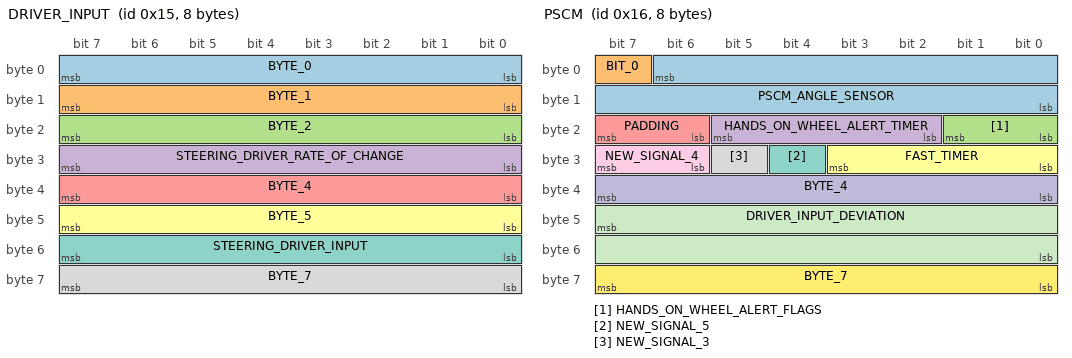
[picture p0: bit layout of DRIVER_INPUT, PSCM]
BO_ 21 DRIVER_INPUT: 8 XXX
 SG_ BYTE_0 : 7|8@0+ (1,0) [0|255] "" XXX
 SG_ BYTE_1 : 15|8@0+ (1,0) [0|255] "" XXX
 SG_ BYTE_2 : 16|8@1+ (1,0) [0|255] "" XXX
 SG_ STEERING_DRIVER_RATE_OF_CHANGE : 31|8@0- (1,0) [0|255] "" XXX
 SG_ BYTE_4 : 39|8@0+ (1,0) [0|255] "" XXX
 SG_ BYTE_5 : 40|8@1+ (1,0) [0|255] "" XXX
 SG_ STEERING_DRIVER_INPUT : 55|8@0- (1,1) [0|255] "" XXX
 SG_ BYTE_7 : 63|8@0+ (1,0) [0|255] "" XXX

BO_ 22 PSCM: 8 XXX
 SG_ PSCM_ANGLE_SENSOR : 6|15@0- (0.05596,0) [-916|916] "º" XXX
 SG_ BIT_0 : 7|1@0+ (1,0) [0|1] "" XXX
 SG_ HANDS_ON_WHEEL_ALERT_FLAGS : 17|2@0+ (1,0) [0|3] "" XXX
 SG_ HANDS_ON_WHEEL_ALERT_TIMER : 21|4@0+ (1,0) [0|15] "" XXX
 SG_ PADDING : 23|2@0+ (1,0) [0|3] "" XXX
 SG_ FAST_TIMER : 27|4@0+ (1,0) [0|15] "" XXX
 SG_ NEW_SIGNAL_5 : 28|1@0+ (1,0) [0|1] "" XXX
 SG_ NEW_SIGNAL_3 : 29|1@0+ (1,0) [0|1] "" XXX
 SG_ NEW_SIGNAL_4 : 31|2@0+ (1,0) [0|3] "" XXX
 SG_ BYTE_4 : 39|8@0+ (1,0) [0|255] "" XXX
 SG_ DRIVER_INPUT_DEVIATION : 47|16@0- (1,0) [0|65535] "" XXX
 SG_ BYTE_7 : 63|8@0+ (1,0) [0|255] "" XXX

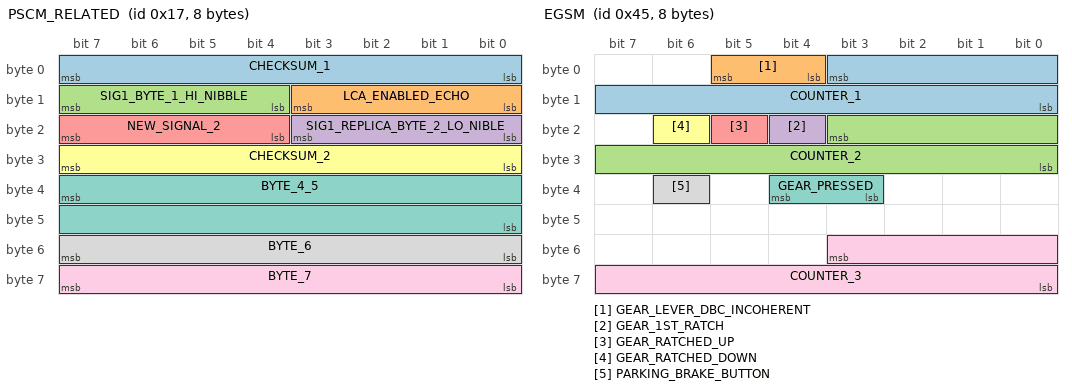
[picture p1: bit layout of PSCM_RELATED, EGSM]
BO_ 23 PSCM_RELATED: 8 XXX
 SG_ CHECKSUM_1 : 7|8@0+ (1,0) [0|255] "" XXX
 SG_ LCA_ENABLED_ECHO : 11|4@0+ (1,0) [0|15] "" XXX
 SG_ SIG1_BYTE_1_HI_NIBBLE : 15|4@0+ (1,0) [0|15] "" XXX
 SG_ SIG1_REPLICA_BYTE_2_LO_NIBLE : 19|4@0+ (1,0) [0|15] "" XXX
 SG_ NEW_SIGNAL_2 : 23|4@0+ (1,0) [0|15] "" XXX
 SG_ CHECKSUM_2 : 31|8@0+ (1,0) [0|255] "" XXX
 SG_ BYTE_4_5 : 39|16@0+ (1,0) [0|65535] "" XXX
 SG_ BYTE_6 : 55|8@0+ (1,0) [0|255] "" XXX
 SG_ BYTE_7 : 63|8@0+ (1,0) [0|255] "" XXX

BO_ 69 EGSM: 8 XXX
 SG_ COUNTER_1 : 3|12@0+ (1,0) [0|4095] "" XXX
 SG_ GEAR_LEVER_DBC_INCOHERENT : 5|2@0+ (1,0) [0|3] "" XXX
 SG_ COUNTER_2 : 19|12@0+ (1,0) [0|4095] "" XXX
 SG_ GEAR_1ST_RATCH : 20|1@0+ (1,0) [0|1] "" XXX
 SG_ GEAR_RATCHED_UP : 21|1@0+ (1,0) [0|1] "" XXX
 SG_ GEAR_RATCHED_DOWN : 22|1@0+ (1,0) [0|1] "" XXX
 SG_ GEAR_PRESSED : 36|2@0+ (1,0) [0|3] "" XXX
 SG_ PARKING_BRAKE_BUTTON : 38|1@0+ (1,0) [0|1] "" XXX
 SG_ COUNTER_3 : 51|12@0+ (1,0) [0|4095] "" XXX

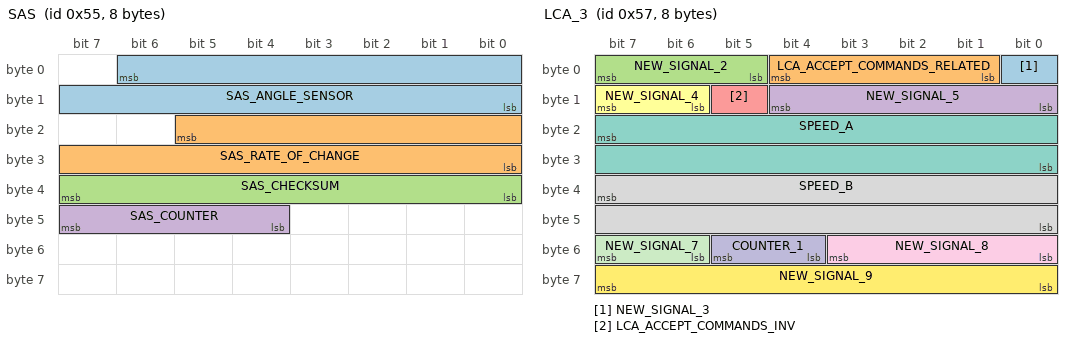
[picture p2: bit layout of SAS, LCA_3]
BO_ 85 SAS: 8 XXX
 SG_ SAS_ANGLE_SENSOR : 6|15@0- (0.05596,0) [0|32767] "º" XXX
 SG_ SAS_RATE_OF_CHANGE : 21|14@0- (1,0) [0|16383] "" XXX
 SG_ SAS_CHECKSUM : 39|8@0+ (1,0) [0|4095] "" XXX
 SG_ SAS_COUNTER : 44|4@1+ (1,0) [0|15] "" XXX

BO_ 87 LCA_3: 8 XXX
 SG_ NEW_SIGNAL_3 : 0|1@0+ (1,0) [0|1] "" XXX
 SG_ LCA_ACCEPT_COMMANDS_RELATED : 4|4@0+ (1,0) [0|15] "" XXX
 SG_ NEW_SIGNAL_2 : 7|3@0+ (1,0) [0|7] "" XXX
 SG_ NEW_SIGNAL_5 : 12|5@0+ (1,0) [0|31] "" XXX
 SG_ LCA_ACCEPT_COMMANDS_INV : 13|1@0+ (1,0) [0|1] "" XXX
 SG_ NEW_SIGNAL_4 : 15|2@0+ (1,0) [0|3] "" XXX
 SG_ SPEED_A : 23|16@0+ (1,0) [0|65535] "" XXX
 SG_ SPEED_B : 39|16@0+ (1,0) [0|65535] "" XXX
 SG_ NEW_SIGNAL_8 : 51|4@0+ (1,0) [0|15] "" XXX
 SG_ COUNTER_1 : 53|2@0+ (1,0) [0|3] "" XXX
 SG_ NEW_SIGNAL_7 : 55|2@0+ (1,0) [0|3] "" XXX
 SG_ NEW_SIGNAL_9 : 63|8@0+ (1,0) [0|255] "" XXX

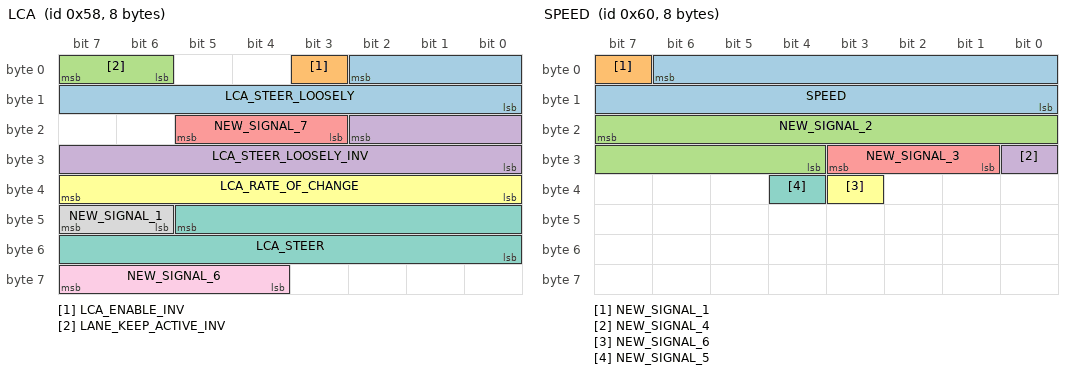
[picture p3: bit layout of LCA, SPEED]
BO_ 88 LCA: 8 XXX
 SG_ LCA_STEER_LOOSELY : 2|11@0- (1,0) [0|2047] "" XXX
 SG_ LCA_ENABLE_INV : 3|1@0+ (1,0) [0|1] "" XXX
 SG_ LANE_KEEP_ACTIVE_INV : 7|2@0+ (1,0) [0|3] "" XXX
 SG_ LCA_STEER_LOOSELY_INV : 18|11@0- (1,0) [0|2047] "" XXX
 SG_ NEW_SIGNAL_7 : 21|3@0+ (1,0) [0|7] "" XXX
 SG_ LCA_RATE_OF_CHANGE : 39|8@0+ (1,0) [0|255] "" XXX
 SG_ LCA_STEER : 45|14@0- (1,0) [0|16383] "" XXX
 SG_ NEW_SIGNAL_1 : 47|2@0+ (1,0) [0|3] "" XXX
 SG_ NEW_SIGNAL_6 : 60|4@1+ (1,0) [0|15] "" XXX

BO_ 96 SPEED: 8 XXX
 SG_ SPEED : 6|15@0+ (1,0) [0|32767] "" XXX
 SG_ NEW_SIGNAL_1 : 7|1@0+ (1,0) [0|1] "" XXX
 SG_ NEW_SIGNAL_2 : 23|12@0+ (1,0) [0|4095] "" XXX
 SG_ NEW_SIGNAL_4 : 24|1@0+ (1,0) [0|1] "" XXX
 SG_ NEW_SIGNAL_3 : 27|3@0+ (1,0) [0|7] "" XXX
 SG_ NEW_SIGNAL_6 : 35|1@0+ (1,0) [0|1] "" XXX
 SG_ NEW_SIGNAL_5 : 36|1@0+ (1,0) [0|1] "" XXX

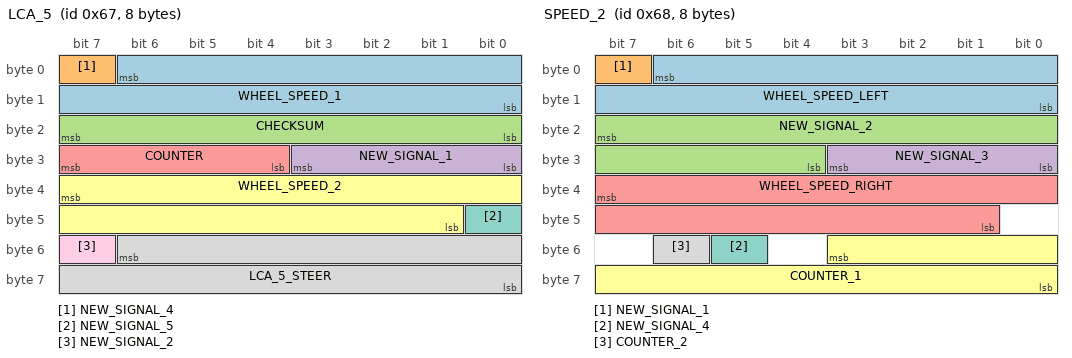
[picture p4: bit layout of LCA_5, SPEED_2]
BO_ 103 LCA_5: 8 XXX
 SG_ WHEEL_SPEED_1 : 6|15@0+ (0.1,0) [0|255] "rpm" XXX
 SG_ NEW_SIGNAL_4 : 7|1@0+ (1,0) [0|1] "" XXX
 SG_ CHECKSUM : 23|8@0+ (1,0) [0|4095] "" XXX
 SG_ NEW_SIGNAL_1 : 24|4@1+ (1,0) [0|15] "" XXX
 SG_ COUNTER : 28|4@1+ (1,0) [0|15] "" XXX
 SG_ WHEEL_SPEED_2 : 39|15@0+ (0.1,0) [0|32767] "rpm" XXX
 SG_ NEW_SIGNAL_5 : 40|1@0+ (1,0) [0|1] "" XXX
 SG_ LCA_5_STEER : 54|15@0- (0.05596,0) [0|32767] "deg" XXX
 SG_ NEW_SIGNAL_2 : 55|1@0+ (1,0) [0|1] "" XXX

BO_ 104 SPEED_2: 8 XXX
 SG_ WHEEL_SPEED_LEFT : 6|15@0+ (1,0) [0|32767] "" XXX
 SG_ NEW_SIGNAL_1 : 7|1@0+ (1,0) [0|1] "" XXX
 SG_ NEW_SIGNAL_2 : 23|12@0+ (1,0) [0|4095] "" XXX
 SG_ NEW_SIGNAL_3 : 27|4@0+ (1,0) [0|15] "" XXX
 SG_ WHEEL_SPEED_RIGHT : 39|15@0+ (1,0) [0|32767] "" XXX
 SG_ COUNTER_1 : 51|12@0+ (1,0) [0|4095] "" XXX
 SG_ NEW_SIGNAL_4 : 53|1@0+ (1,0) [0|1] "" XXX
 SG_ COUNTER_2 : 54|1@0+ (1,0) [0|1] "" XXX

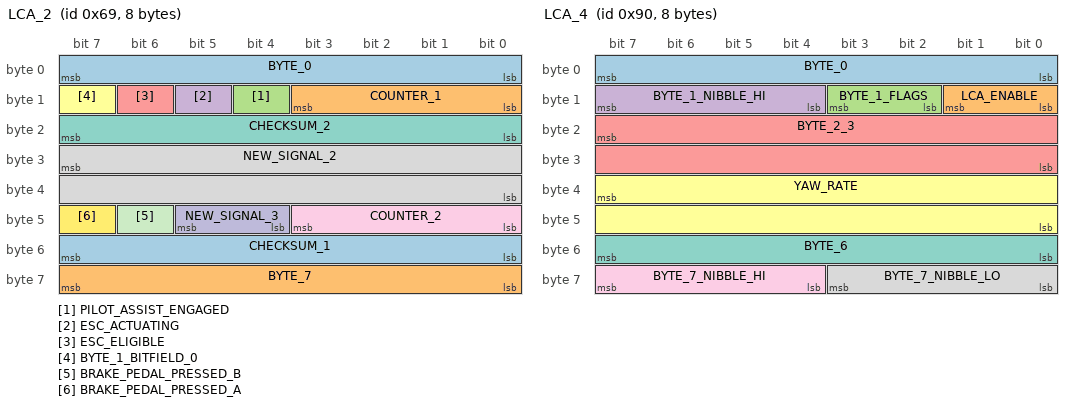
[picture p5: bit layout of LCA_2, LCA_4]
BO_ 105 LCA_2: 8 XXX
 SG_ BYTE_0 : 7|8@0+ (1,0) [0|2047] "" XXX
 SG_ COUNTER_1 : 11|4@0+ (1,0) [0|4095] "" XXX
 SG_ PILOT_ASSIST_ENGAGED : 12|1@0+ (1,0) [0|1] "" XXX
 SG_ ESC_ACTUATING : 13|1@0+ (1,0) [0|1] "" XXX
 SG_ ESC_ELIGIBLE : 14|1@0+ (1,0) [0|1] "" XXX
 SG_ BYTE_1_BITFIELD_0 : 15|1@0+ (1,0) [0|7] "" XXX
 SG_ CHECKSUM_2 : 23|8@0+ (1,0) [0|255] "" XXX
 SG_ NEW_SIGNAL_2 : 31|16@0+ (1,0) [0|65535] "" XXX
 SG_ COUNTER_2 : 43|4@0+ (1,0) [0|4095] "" XXX
 SG_ NEW_SIGNAL_3 : 45|2@0+ (1,0) [0|3] "" XXX
 SG_ BRAKE_PEDAL_PRESSED_B : 46|1@0+ (1,0) [0|1] "" XXX
 SG_ BRAKE_PEDAL_PRESSED_A : 47|1@0+ (-1,1) [0|1] "" XXX
 SG_ CHECKSUM_1 : 55|8@0+ (1,0) [0|255] "" XXX
 SG_ BYTE_7 : 63|8@0+ (1,0) [0|255] "" XXX

BO_ 128 GEAR_POSITION: 8 XXX
 SG_ NEW_SIGNAL_3 : 3|4@0+ (1,0) [0|15] "" XXX
 SG_ NEW_SIGNAL_2 : 4|1@0+ (1,0) [0|1] "" XXX
 SG_ NEW_SIGNAL_1 : 7|3@0+ (1,0) [0|7] "" XXX
 SG_ NEW_SIGNAL_5 : 11|4@0+ (1,0) [0|15] "" XXX
 SG_ NEW_SIGNAL_4 : 15|4@0+ (1,0) [0|15] "" XXX
 SG_ NEW_SIGNAL_17 : 17|2@0+ (1,0) [0|3] "" XXX
 SG_ AEB_A : 18|1@0+ (1,0) [0|1] "" XXX
 SG_ NEW_SIGNAL_18 : 19|1@0+ (1,0) [0|1] "" XXX
 SG_ AEB_B : 20|1@0+ (1,0) [0|1] "" XXX
 SG_ NEW_SIGNAL_6 : 23|3@0+ (1,0) [0|255] "" XXX
 SG_ NEW_SIGNAL_7 : 24|8@1+ (1,0) [0|255] "" XXX
 SG_ NEW_SIGNAL_8 : 39|8@0+ (1,0) [0|255] "" XXX
 SG_ NEW_SIGNAL_13 : 43|4@0+ (1,0) [0|15] "" XXX
 SG_ NEW_SIGNAL_10 : 46|3@0+ (1,0) [0|7] "" XXX
 SG_ NEW_SIGNAL_9 : 47|1@0+ (1,0) [0|1] "" XXX
 SG_ NEW_SIGNAL_14 : 51|4@0+ (1,0) [0|15] "" XXX
 SG_ NEW_SIGNAL_12 : 54|3@0+ (1,0) [0|7] "" XXX
 SG_ NEW_SIGNAL_11 : 55|1@0+ (1,0) [0|1] "" XXX
 SG_ GEAR_POSITION : 58|3@0+ (1,0) [0|7] "" XXX
 SG_ NEW_SIGNAL_16 : 62|4@0+ (1,0) [0|15] "" XXX
 SG_ NEW_SIGNAL_15 : 63|1@0+ (1,0) [0|1] "" XXX

BO_ 144 LCA_4: 8 XXX
 SG_ BYTE_0 : 7|8@0+ (1,0) [0|16383] "" XXX
 SG_ LCA_ENABLE : 9|2@0+ (1,0) [0|3] "" XXX
 SG_ BYTE_1_FLAGS : 11|2@0+ (1,0) [0|3] "" XXX
 SG_ BYTE_1_NIBBLE_HI : 15|4@0+ (1,0) [0|63] "" XXX
 SG_ BYTE_2_3 : 23|16@0- (1,0) [0|65535] "" XXX
 SG_ YAW_RATE : 39|16@0- (1,0) [0|65535] "" XXX
 SG_ BYTE_6 : 55|8@0+ (1,0) [0|255] "" XXX
 SG_ BYTE_7_NIBBLE_LO : 59|4@0+ (1,0) [0|15] "" XXX
 SG_ BYTE_7_NIBBLE_HI : 60|4@1+ (1,0) [0|15] "" XXX

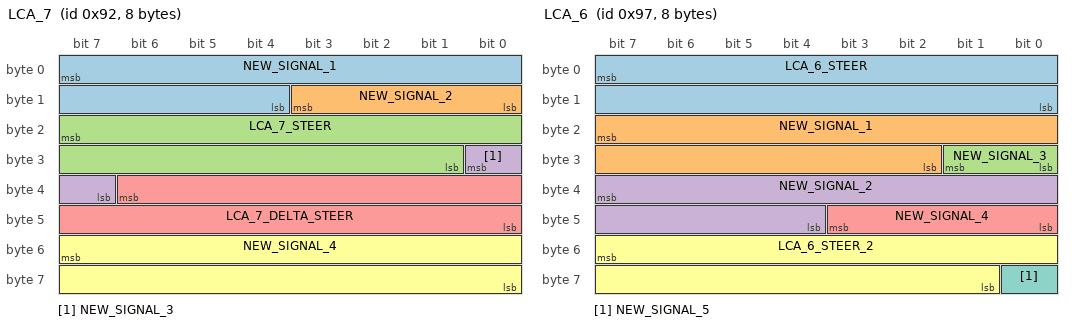
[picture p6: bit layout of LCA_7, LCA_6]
BO_ 146 LCA_7: 8 XXX
 SG_ NEW_SIGNAL_1 : 7|12@0+ (1,0) [0|4095] "" XXX
 SG_ NEW_SIGNAL_2 : 11|4@0+ (1,0) [0|15] "" XXX
 SG_ LCA_7_STEER : 23|15@0- (1,0) [0|32767] "" XXX
 SG_ NEW_SIGNAL_3 : 24|2@0+ (1,0) [0|3] "" XXX
 SG_ LCA_7_DELTA_STEER : 38|15@0- (1,0) [0|32767] "" XXX
 SG_ NEW_SIGNAL_4 : 55|16@0+ (1,0) [0|65535] "" XXX

BO_ 151 LCA_6: 8 XXX
 SG_ LCA_6_STEER : 7|16@0- (1,0) [0|65535] "" XXX
 SG_ NEW_SIGNAL_1 : 23|14@0- (1,0) [0|16383] "" XXX
 SG_ NEW_SIGNAL_3 : 25|2@0+ (1,0) [0|3] "" XXX
 SG_ NEW_SIGNAL_2 : 39|12@0+ (1,0) [0|4095] "" XXX
 SG_ NEW_SIGNAL_4 : 43|4@0+ (1,0) [0|15] "" XXX
 SG_ LCA_6_STEER_2 : 55|15@0- (1,0) [0|32767] "" XXX
 SG_ NEW_SIGNAL_5 : 56|1@0+ (1,0) [0|1] "" XXX

BO_ 336 NEW_MSG_150: 8 XXX
 SG_ IGN_DRAFT : 5|2@0+ (1,0) [0|3] "" XXX

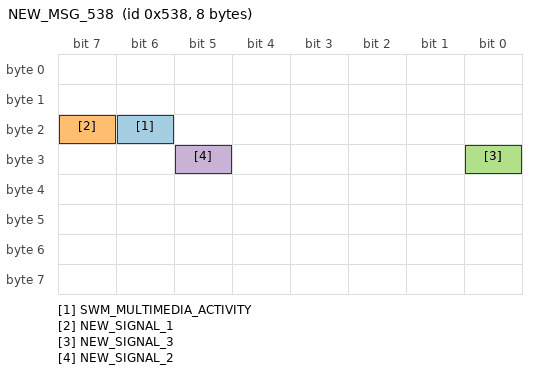
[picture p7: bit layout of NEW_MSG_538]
BO_ 1336 NEW_MSG_538: 8 XXX
 SG_ SWM_MULTIMEDIA_ACTIVITY : 22|1@0+ (1,0) [0|1] "" XXX
 SG_ NEW_SIGNAL_1 : 23|1@0+ (1,0) [0|1] "" XXX
 SG_ NEW_SIGNAL_3 : 24|1@0+ (1,0) [0|1] "" XXX
 SG_ NEW_SIGNAL_2 : 29|1@0+ (1,0) [0|1] "" XXX

CM_ SG_ 22 HANDS_ON_WHEEL_ALERT_TIMER "0: hands on wheel; 1-13: counts up 1 per second; 14: hands on wheel warning displayed; 15: hands on wheel alert displayed";
CM_ SG_ 22 FAST_TIMER "unknown purpose or what it's doing";
CM_ BO_ 23 "Might be related to PSCM 0x16";
CM_ SG_ 87 LCA_ACCEPT_COMMANDS_RELATED "Goes to 15 when actively operating LCA";
CM_ SG_ 87 LCA_ACCEPT_COMMANDS_INV "Goes to 0 when PSCM allowed to receive LCA commands";
CM_ SG_ 88 LCA_ENABLE_INV "Master enable, active-low";
CM_ SG_ 103 WHEEL_SPEED_1 "Possible Front Left  (FL)";
CM_ SG_ 103 WHEEL_SPEED_2 "Possible Front Right (FR)";
CM_ SG_ 105 ESC_ACTUATING "Goes to 1 in combination with ESC_ELIGIBLE when ESC is actively actuating";
CM_ SG_ 105 ESC_ELIGIBLE "Goes to 1 on e.g. speed bump, but doesn't trigger any intervention";
VAL_ 22 HANDS_ON_WHEEL_ALERT_FLAGS 0 "LCA not active" 1 "Alert Active" 3 "Follow Timer";
VAL_ 128 GEAR_POSITION 0 "Park" 1 "Reverse" 2 "Neutral" 3 "Drive" 4 "B-Mode";
